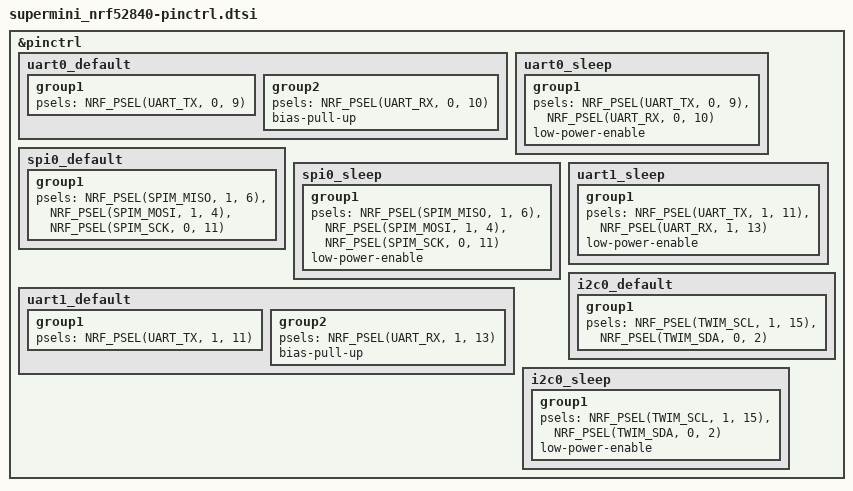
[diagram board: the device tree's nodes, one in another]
/*
 * Copyright (c) 2022 Nordic Semiconductor
 * SPDX-License-Identifier: Apache-2.0
 */

 &pinctrl {
	uart0_default: uart0_default {
		group1 {
			psels = <NRF_PSEL(UART_TX, 0, 9)>;
		};

		group2 {
			psels = <NRF_PSEL(UART_RX, 0, 10)>;
			bias-pull-up;
		};
	};

	uart0_sleep: uart0_sleep {
		group1 {
			psels = <NRF_PSEL(UART_TX, 0, 9)>,
				<NRF_PSEL(UART_RX, 0, 10)>;
			low-power-enable;
		};
	};	

	spi0_default: spi0_default {
		group1 {
			psels = <NRF_PSEL(SPIM_MISO, 1, 6)>,
					<NRF_PSEL(SPIM_MOSI, 1, 4)>,
					<NRF_PSEL(SPIM_SCK, 0, 11)>;
		};
	};

	spi0_sleep: spi0_sleep {
		group1 {
			psels = <NRF_PSEL(SPIM_MISO, 1, 6)>,
					<NRF_PSEL(SPIM_MOSI, 1, 4)>,
					<NRF_PSEL(SPIM_SCK, 0, 11)>;
			low-power-enable;
		};
	};	

	uart1_default: uart1_default {
		group1 {
			psels = <NRF_PSEL(UART_TX, 1, 11)>;
		};

		group2 {
			psels = <NRF_PSEL(UART_RX, 1, 13)>;
			bias-pull-up;
		};
	};

	uart1_sleep: uart1_sleep {
		group1 {
			psels = <NRF_PSEL(UART_TX, 1, 11)>,
				<NRF_PSEL(UART_RX, 1, 13)>;
			low-power-enable;
		};
	};	

	i2c0_default: i2c0_default {
		group1 {
			psels = <NRF_PSEL(TWIM_SCL, 1, 15)>, <NRF_PSEL(TWIM_SDA, 0, 2)>;
		};
	};

	i2c0_sleep: i2c0_sleep {
		group1 {
			psels = <NRF_PSEL(TWIM_SCL, 1, 15)>, <NRF_PSEL(TWIM_SDA, 0, 2)>;
			low-power-enable;
		};
	};	
};
